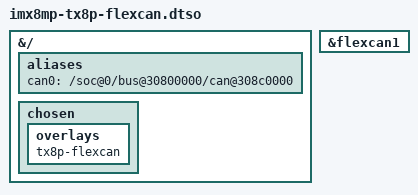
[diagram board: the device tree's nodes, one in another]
// SPDX-License-Identifier: (GPL-2.0 OR MIT)
/*
 * Copyright 2022 Lothar Waßmann <LW@KARO-electronics.de>
 *
 */

/dts-v1/;

/plugin/;

&{/} {
	aliases {
		can0 = "/soc@0/bus@30800000/can@308c0000";
	};

	chosen {
		overlays {
			tx8p-flexcan;
		};
	};
};

&flexcan1 {
	status = "okay";
};
